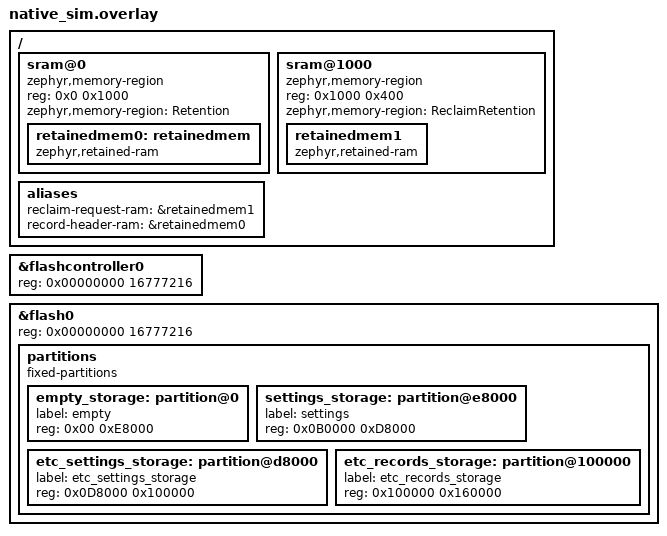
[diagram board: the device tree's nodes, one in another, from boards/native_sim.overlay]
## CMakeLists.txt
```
#SPDX - License - Identifier : Apache - 2.0

cmake_minimum_required(VERSION 3.20.0)
find_package(Zephyr REQUIRED HINTS $ENV{ZEPHYR_BASE})
project(etc_device_record_test)

FILE(GLOB app_sources src/*.c
                      src/mock/*.c
                      src/mock/zephyr/drivers/*.c)
target_sources(app PRIVATE ${app_sources})
set(APP_SRC_DIR ../../../../applications/etc-app/src)
set(MEMFAULT_SDK_ROOT $ENV{ZEPHYR_BASE}/../modules/lib/memfault-firmware-sdk)

target_compile_options(app PRIVATE -Wno-error=double-promotion)

target_sources(app PRIVATE 
                ${APP_SRC_DIR}/exact/etc_devices/etc_device.c
                ${APP_SRC_DIR}/exact/etc_devices/etc_device_record.c
                ${APP_SRC_DIR}/exact/etc_memfault/etc_memfault_dummy.c
                ${APP_SRC_DIR}/exact/etc_memfault/etc_memfault_event.c
                ${APP_SRC_DIR}/exact/etc_util/etc_util.c
                ${MEMFAULT_SDK_ROOT}/components/util/src/memfault_circular_buffer.c
                ${MEMFAULT_SDK_ROOT}/components/util/src/memfault_minimal_cbor.c
                ${MEMFAULT_SDK_ROOT}/components/core/src/memfault_batched_events.c
)

target_include_directories(app PRIVATE
                            src
                            src/mock
                            src/mock/zephyr/drivers
                            ${APP_SRC_DIR}/exact/etc_devices
                            ${APP_SRC_DIR}/exact/etc_memfault
                            ${APP_SRC_DIR}/exact/etc_settings
                            ${APP_SRC_DIR}/exact/etc_sensor
                            ${APP_SRC_DIR}/exact/etc_util
                            ${APP_SRC_DIR}/exact/etc_calibration
                            ${APP_SRC_DIR}
                            ${MEMFAULT_SDK_ROOT}/components/include
)

zephyr_compile_definitions(IMAGE_HASH_LEN=32)
zephyr_compile_definitions(CONFIG_ETC_APP_LOG_LEVEL=4)
zephyr_compile_definitions(CONFIG_ETC_DEVICE_RELAY_MAX_RECORD_HISTORY=64)
zephyr_compile_definitions(CONFIG_ETC_DEVICE_SAVE_RECORD_SEC=1)
zephyr_compile_definitions(CONFIG_MEMFAULT_ETC_EVENT_NOINIT_SIZE=2048)
```

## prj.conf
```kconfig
CONFIG_ZTEST=y
CONFIG_HEAP_MEM_POOL_SIZE=8192
CONFIG_RETAINED_MEM=y

CONFIG_FLASH=y
CONFIG_FLASH_PAGE_LAYOUT=y
CONFIG_FLASH_MAP=y
CONFIG_NVS=y

# Settings - Used to store real-time device configuration to flash.
CONFIG_SETTINGS=y
CONFIG_SETTINGS_FCB=y
CONFIG_FCB=y

CONFIG_POSIX_API=y

# Application Event Manager
CONFIG_APP_EVENT_MANAGER=y
CONFIG_APP_EVENT_MANAGER_LOG_EVENT_TYPE=n
```

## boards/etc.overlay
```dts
/ {
	sram@2003F000 {
		compatible = "zephyr,memory-region", "mmio-sram";
		reg = <0x2003F000 0x1000>;
		zephyr,memory-region = "RetainedMem";
		status = "okay";

		retainedmem0: retainedmem {
			compatible = "zephyr,retained-ram";
			status = "okay";
	        };
        };

	aliases {
		record-header-ram = &retainedmem0;
	};
};
```

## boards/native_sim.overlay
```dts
/ {
	sram@0 {
		compatible = "zephyr,memory-region";
		reg = <0x0 0x1000>;
		status = "okay";
		zephyr,memory-region = "Retention";

		retainedmem0: retainedmem {
			compatible = "zephyr,retained-ram";
			status = "okay";
		};
	};
	sram@1000 {
		compatible = "zephyr,memory-region";
		reg = <0x1000 0x400>;
		status = "okay";
		zephyr,memory-region = "ReclaimRetention";

		retainedmem1: retainedmem1 {
			compatible = "zephyr,retained-ram";
			status = "okay";
		};
	};

	aliases {
		reclaim-request-ram = &retainedmem1;
		record-header-ram = &retainedmem0;
	};
};

&flashcontroller0 {
	reg = <0x00000000 16777216>;
};

&flash0 {
	reg = <0x00000000 16777216>;

	partitions {
		compatible = "fixed-partitions";
		#address-cells = <1>;
		#size-cells = <1>;

		/delete-node/ boot_partition;
		/delete-node/ slot0_partition;
		/delete-node/ slot1_partition;
		/delete-node/ scratch_partition;
		/delete-node/ storage_partition;

		empty_storage: partition@0 {
			label = "empty";
			reg = < 0x00 0xE8000 >;
		};
		settings_storage: partition@e8000 {
			label = "settings";
			reg = < 0x0B0000 0xD8000 >;
		};
		etc_settings_storage: partition@d8000 {
			label = "etc_settings_storage";
			reg = < 0x0D8000 0x100000 >;
		};
		etc_records_storage: partition@100000 {
			label = "etc_records_storage";
			reg = < 0x100000 0x160000 >;
		};
	};
};
```

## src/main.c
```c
/*
 * Copyright (c) 2024 EXACT Technology Corporation
 */

#include <stdbool.h>
#include <string.h>
#include <zephyr/ztest.h>

#include "etc_device.h"
#include "etc_device_record.h"
#include "etc_memfault_event.h"
#include "etc_util.h"
#include <zephyr/drivers/retained_mem.h>
#include <zephyr/logging/log.h>
#include <zephyr/random/random.h>

LOG_MODULE_REGISTER(etc_mlf_event_test, CONFIG_ETC_APP_LOG_LEVEL);

extern bool prv_platform_nv_event_storage_enabled(void);
extern bool prv_platform_nv_event_storage_read_has_event(size_t *event_size);
extern bool prv_platform_nv_event_storage_read(uint32_t offset, void *buf, size_t buf_len);
extern void prv_platform_nv_event_storage_consume(void);
extern bool prv_platform_nv_event_storage_write(MemfaultEventReadCallback event_read_cb,
						size_t total_size);

static int select_event = 0;

typedef struct {
	const uint8_t *data;
	size_t written;
	size_t len;
} sFakePersistedEvent;

const uint8_t test_event0[] = {
	0xa7, 0x02, 0x01, 0x03, 0x01, 0x07, 0x69, 'D', 'A', 'A',  'B',	'B', 'C',
	'C',  'D',  'D',  0x0a, 0x64, 'm',  'a',  'i', 'n', 0x09, 0x65, '1', '.',
	'2',  '.',  '3',  0x06, 0x66, 'e',  'v',  't', '_', '2',  '4',
};

const uint8_t test_event1[] = {
	0xa6, 0x02, 0x01, 0x03, 0x01, 0x0a, 0x64, 'm', 'a', 'i', 'n', 0x09, 0x65,
	'1',  '.',  '2',  '.',	'3',  0x06, 0x66, 'e', 'v', 't', '_', '2',  '4',
};

static sFakePersistedEvent s_fake_persisted_events[] = {
	{.data = &test_event0[0], .len = sizeof(test_event0), .written = 0},
	{.data = &test_event1[0], .len = sizeof(test_event1), .written = 0},
};

static bool MemfaultEventReadCallbackHandler(uint32_t offset, void *buf, size_t buf_len)
{
	sFakePersistedEvent *event = &s_fake_persisted_events[select_event];
	memcpy(buf, &event->data[event->written], buf_len);
	event->written += buf_len;
	return true;
}

static void MemfaultEventReset(void)
{
	sFakePersistedEvent *event = &s_fake_persisted_events[select_event];
	event->written = 0;
}

static size_t MemfaultEventReadEventLen(void)
{
	sFakePersistedEvent *event = &s_fake_persisted_events[select_event];
	return event->len;
}

static uint8_t *MemfaultEventReadEventData(void)
{
	sFakePersistedEvent *event = &s_fake_persisted_events[select_event];
	return (uint8_t *)event->data;
}

void memfault_sdk_assert_func(void)
{
}

static void *test_setup(void)
{
	memfault_etc_event_init();
	return NULL;
}

static void test_teardown(void *)
{
	/* Allow ack/nack status to be saved to flash */
	k_sleep(K_SECONDS(CONFIG_ETC_DEVICE_SAVE_RECORD_SEC + 1));
}

ZTEST(etc_mlf_event_test, test_mutliples_events)
{
	select_event = 0;
	bool rc = true;
	size_t event_size = 0;
	uint8_t buf[128] = {0x00};
	MemfaultEventReset();
	rc = prv_platform_nv_event_storage_write(MemfaultEventReadCallbackHandler,
						 MemfaultEventReadEventLen());
	zassert_true(rc);
	rc = prv_platform_nv_event_storage_read_has_event(&event_size);
	zassert_true(rc);
	rc = prv_platform_nv_event_storage_read(0, buf, event_size);
	zassert_true(rc);
	zassert_equal(event_size, MemfaultEventReadEventLen());
	rc = memcmp(buf, MemfaultEventReadEventData(), event_size);
	zassert_ok(rc);
	prv_platform_nv_event_storage_consume();
	select_event = 1;
	MemfaultEventReset();
	rc = prv_platform_nv_event_storage_write(MemfaultEventReadCallbackHandler,
						 MemfaultEventReadEventLen());
	zassert_true(rc);
	rc = prv_platform_nv_event_storage_read_has_event(&event_size);
	zassert_true(rc);
	rc = prv_platform_nv_event_storage_read(0, buf, event_size);
	zassert_true(rc);
	zassert_equal(event_size, MemfaultEventReadEventLen());
	rc = memcmp(buf, MemfaultEventReadEventData(), event_size);
	prv_platform_nv_event_storage_consume();
}

ZTEST_SUITE(etc_mlf_event_test, NULL, test_setup, NULL, NULL, test_teardown);
```
